# MK65F18 register map
Vendor: NXP Semiconductors; Series: Kinetis_K; File version: 1.6
CPU: CM4 r0p1, little endian, no MPU, FPU, VTOR, 4 interrupt priority bits
Registers are 32-bit, read-write, reset 0x0 unless marked. A register's access mark holds for its fields unless they carry their own. Offsets are from the block's base; [hi:lo] are bit positions; {n}, {i} and the like mark numbered series.

## MCG — Multipurpose Clock Generator module
Base 0x40064000; register names take the prefix MCG_
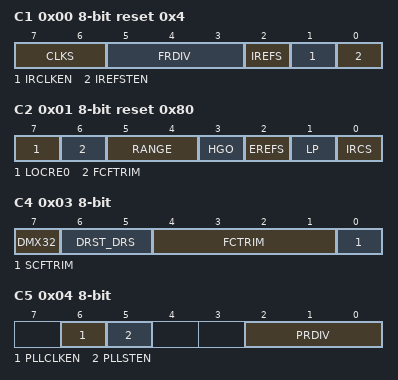
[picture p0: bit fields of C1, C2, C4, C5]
0x00 C1 8-bit reset 0x4 — MCG Control 1 Register
  [7:6] CLKS — Clock Source Select
    0=Encoding 0 - Output of FLL or PLLCS is selected (depends on PLLS control bit); 1=Encoding 1 - Internal reference clock is selected; 2=Encoding 2 - External reference clock is selected; 3=Encoding 3 - Reserved
  [5:3] FRDIV — FLL External Reference Divider
    0=If RANGE = 0 or OSCSEL=1 , Divide Factor is 1; for all other RANGE values, Divide Factor is 32; 1=If RANGE = 0 or OSCSEL=1 , Divide Factor is 2; for all other RANGE values, Divide Factor is 64; 2=If RANGE = 0 or OSCSEL=1 , Divide Factor is 4; for all other RANGE values, Divide Factor is 128; 3=If RANGE = 0 or OSCSEL=1 , Divide Factor is 8; for all other RANGE values, Divide Factor is 256; 4=If RANGE = 0 or OSCSEL=1 , Divide Factor is 16; for all other RANGE values, Divide Factor is 512; 5=If RANGE = 0 or OSCSEL=1 , Divide Factor is 32; for all other RANGE values, Divide Factor is 1024; 6=If RANGE = 0 or OSCSEL=1 , Divide Factor is 64; for all other RANGE values, Divide Factor is 1280 ; 7=If RANGE = 0 or OSCSEL=1 , Divide Factor is 128; for all other RANGE values, Divide Factor is 1536 
  [2] IREFS — Internal Reference Select
    0=External reference clock is selected; 1=The slow internal reference clock is selected
  [1] IRCLKEN — Internal Reference Clock Enable
    0=MCGIRCLK inactive; 1=MCGIRCLK active
  [0] IREFSTEN — Internal Reference Stop Enable
    0=Internal reference clock is disabled in Stop mode; 1=Internal reference clock is enabled in Stop mode if IRCLKEN is set or if MCG is in FEI, FBI, or BLPI modes before entering Stop mode
0x01 C2 8-bit reset 0x80 — MCG Control 2 Register
  [7] LOCRE0 — Loss of Clock Reset Enable
    0=Interrupt request is generated on a loss of OSC0 external reference clock; 1=Generate a reset request on a loss of OSC0 external reference clock
  [6] FCFTRIM — Fast Internal Reference Clock Fine Trim
  [5:4] RANGE — Frequency Range Select
    0=Encoding 0 - Low frequency range selected for the crystal oscillator ; 1=Encoding 1 - High frequency range selected for the crystal oscillator 
  [3] HGO — High Gain Oscillator Select
    0=Configure crystal oscillator for low-power operation; 1=Configure crystal oscillator for high-gain operation
  [2] EREFS — External Reference Select
    0=External reference clock requested; 1=Oscillator requested
  [1] LP — Low Power Select
    0=FLL or PLL is not disabled in bypass modes; 1=FLL or PLL is disabled in bypass modes (lower power)
  [0] IRCS — Internal Reference Clock Select
    0=Slow internal reference clock selected; 1=Fast internal reference clock selected
0x02 C3 8-bit reset not defined — MCG Control 3 Register
  [7:0] SCTRIM — Slow Internal Reference Clock Trim Setting
0x03 C4 8-bit (reset mask 0xE0) — MCG Control 4 Register
  [7] DMX32 — DCO Maximum Frequency with 32.768 kHz Reference
    0=DCO has a default range of 25%; 1=DCO is fine-tuned for maximum frequency with 32.768 kHz reference
  [6:5] DRST_DRS — DCO Range Select
    0=Encoding 0 - Low range (reset default); 1=Encoding 1 - Mid range; 2=Encoding 2 - Mid-high range; 3=Encoding 3 - High range
  [4:1] FCTRIM — Fast Internal Reference Clock Trim Setting
  [0] SCFTRIM — Slow Internal Reference Clock Fine Trim
0x04 C5 8-bit — MCG Control 5 Register
  [6] PLLCLKEN — PLL Clock Enable
    0=MCGPLLCLK is inactive; 1=MCGPLLCLK is active
  [5] PLLSTEN — PLL Stop Enable
    0=MCGPLLCLK and MCGPLLCLK2X are disabled in any of the Stop modes; 1=MCGPLLCLK and MCGPLLCLK2X are enabled if system is in Normal Stop mode
  [2:0] PRDIV — PLL External Reference Divider
    {v}=Divide Factor is {v+1} (v=0..7)
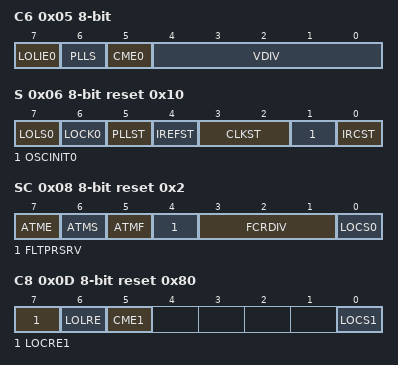
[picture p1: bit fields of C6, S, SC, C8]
0x05 C6 8-bit — MCG Control 6 Register
  [7] LOLIE0 — Loss of Lock Interrrupt Enable
    0=No interrupt request is generated on loss of lock; 1=Generate an interrupt request on loss of lock
  [6] PLLS — PLL Select
    0=FLL is selected; 1=PLLCS output clock is selected (PRDIV0 bits of PLL in the C5 register need to be programmed to the correct divider to generate a PLL reference clock in the range specified in the data sheet (fpll_ref) prior to setting the PLLS bit)
  [5] CME0 — Clock Monitor Enable
    0=External clock monitor is disabled for OSC0; 1=External clock monitor is enabled for OSC0
  [4:0] VDIV — VCO Divider
    {v}=Multiply Factor is {v+16} (v=0..31)
0x06 S 8-bit reset 0x10 — MCG Status Register
  [7] LOLS0 — Loss of Lock Status
    0=PLL has not lost lock since LOLS 0 was last cleared; 1=PLL has lost lock since LOLS 0 was last cleared
  [6] LOCK0 ro — Lock Status
    0=PLL is currently unlocked; 1=PLL is currently locked
  [5] PLLST ro — PLL Select Status
    0=Source of PLLS clock is FLL clock; 1=Source of PLLS clock is PLLCS output clock
  [4] IREFST ro — Internal Reference Status
    0=Source of FLL reference clock is the external reference clock; 1=Source of FLL reference clock is the internal reference clock
  [3:2] CLKST ro — Clock Mode Status
    0=Encoding 0 - Output of the FLL is selected (reset default); 1=Encoding 1 - Internal reference clock is selected; 2=Encoding 2 - External reference clock is selected; 3=Encoding 3 - Output of the PLL is selected
  [1] OSCINIT0 ro — OSC Initialization
  [0] IRCST ro — Internal Reference Clock Status
    0=Source of internal reference clock is the slow clock (32 kHz IRC); 1=Source of internal reference clock is the fast clock (4 MHz IRC)
0x08 SC 8-bit reset 0x2 — MCG Status and Control Register
  [7] ATME — Automatic Trim Machine Enable
    0=Auto Trim Machine disabled; 1=Auto Trim Machine enabled
  [6] ATMS — Automatic Trim Machine Select
    0=32 kHz Internal Reference Clock selected; 1=4 MHz Internal Reference Clock selected
  [5] ATMF — Automatic Trim Machine Fail Flag
    0=Automatic Trim Machine completed normally; 1=Automatic Trim Machine failed
  [4] FLTPRSRV — FLL Filter Preserve Enable
    0=FLL filter and FLL frequency will reset on changes to currect clock mode; 1=Fll filter and FLL frequency retain their previous values during new clock mode change
  [3:1] FCRDIV — Fast Clock Internal Reference Divider
    0=Divide Factor is 1; 1=Divide Factor is 2; 2=Divide Factor is 4; 3=Divide Factor is 8; 4=Divide Factor is 16; 5=Divide Factor is 32; 6=Divide Factor is 64; 7=Divide Factor is 128
  [0] LOCS0 — OSC0 Loss of Clock Status
    0=Loss of OSC0 has not occurred; 1=Loss of OSC0 has occurred
0x0A ATCVH 8-bit — MCG Auto Trim Compare Value High Register
  [7:0] ATCVH — ATM Compare Value High
0x0B ATCVL 8-bit — MCG Auto Trim Compare Value Low Register
  [7:0] ATCVL — ATM Compare Value Low
0x0C C7 8-bit — MCG Control 7 Register
  [1:0] OSCSEL — MCG OSC Clock Select
    0=Selects Oscillator (OSCCLK0); 1=Selects 32 kHz RTC Oscillator; 2=Selects Oscillator (OSCCLK1)
0x0D C8 8-bit reset 0x80 — MCG Control 8 Register
  [7] LOCRE1 — Loss of Clock Reset Enable
    0=Interrupt request is generated on a loss of RTC external reference clock; 1=Generate a reset request on a loss of RTC external reference clock
  [6] LOLRE — PLL Loss of Lock Reset Enable
    0=Interrupt request is generated on a PLL loss of lock indication. The PLL loss of lock interrupt enable bit must also be set to generate the interrupt request.; 1=Generate a reset request on a PLL loss of lock indication
  [5] CME1 — Clock Monitor Enable1
    0=External clock monitor is disabled for RTC clock; 1=External clock monitor is enabled for RTC clock
  [0] LOCS1 — RTC Loss of Clock Status
    0=Loss of RTC has not occur; 1=Loss of RTC has occur
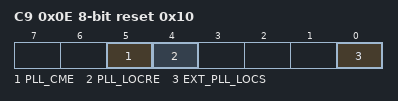
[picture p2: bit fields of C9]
0x0E C9 8-bit reset 0x10 — MCG Control 9 Register
  [5] PLL_CME — MCG External PLL Clock Monitor Enable
    0=External clock monitor is disabled for EXT_PLL clock; 1=External clock monitor is enabled for EXT_PLL clock
  [4] PLL_LOCRE — MCG External PLL Loss of Clock Reset Enable
    0=Interrupt request is generated on a invalid or loss of the MCG external PLL clock; 1=Generates a system reset request on a invalid or loss of the MCG external PLL clock
  [0] EXT_PLL_LOCS — External PLL Loss of Clock Status
    0=Loss of MCG EXT_PLL has not occurred; 1=Loss of MCG EXT_PLL has occurred
0x10 C11 8-bit — MCG Control 11 Register
  [4] PLLCS — PLL Clock Select
    0=PLL0 output clock is selected; 1=External PLL clock is selected
0x12 S2 8-bit ro — MCG Status 2 Register
  [4] PLLCST — PLL Clock Select Status
    0=Source of PLLCS is PLL clock; 1=Source of PLLCS is EXT_PLL clock
